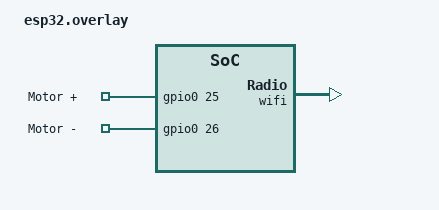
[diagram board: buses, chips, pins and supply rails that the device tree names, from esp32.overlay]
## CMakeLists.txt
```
# SPDX-License-Identifier: Apache-2.0

set(BOARD esp32)
set(CONF_FILE prj.conf)
set(DTC_OVERLAY_FILE esp32.overlay)

cmake_minimum_required(VERSION 3.20.0)

find_package(Zephyr REQUIRED HINTS $ENV{ZEPHYR_BASE})
project(soil_respiration_2023)

include_directories(
                      inc/
                      lib/
                      )

target_sources(app PRIVATE
    src/main.c
    inc/wifi.c
    inc/mqtt.c
    #inc/sockets.c
    inc/sensor.c
    lib/scd30.c
    lib/sensirion_common.c
    inc/ota.c
    inc/motor.c
    inc/ble.c
)
```

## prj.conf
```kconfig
# ############## WIFI ##############
CONFIG_WIFI=y
CONFIG_INIT_STACKS=y
CONFIG_NET_TCP_WORKQ_STACK_SIZE=4096
#CONFIG_HEAP_MEM_POOL_SIZE=98304
CONFIG_HEAP_MEM_POOL_SIZE=60000
CONFIG_NET_L2_WIFI_MGMT=y

CONFIG_NETWORKING=y
CONFIG_NET_IPV4=y
CONFIG_NET_TCP=y
CONFIG_NET_IPV6=n
CONFIG_NET_UDP=y


CONFIG_WIFI_ESP32=y
CONFIG_NET_DHCPV4=y
CONFIG_ESP32_WIFI_STA_AUTO_DHCPV4=y

CONFIG_NET_CONFIG_SETTINGS=y
CONFIG_NET_CONFIG_NEED_IPV4=y

CONFIG_DNS_RESOLVER=y
#CONFIG_DNS_RESOLVER_AI_MAX_ENTRIES=10
CONFIG_NET_SOCKETS=y
CONFIG_DNS_SERVER_IP_ADDRESSES=y
CONFIG_DNS_RESOLVER_ADDITIONAL_BUF_CTR=2



CONFIG_NET_CONFIG_SETTINGS=y

CONFIG_NET_TX_STACK_SIZE=2048
CONFIG_NET_RX_STACK_SIZE=2048

CONFIG_NET_PKT_RX_COUNT=10
CONFIG_NET_PKT_TX_COUNT=10
CONFIG_NET_BUF_RX_COUNT=20
CONFIG_NET_BUF_TX_COUNT=20
CONFIG_NET_MAX_CONTEXTS=10

#Ethernet - building without CONFIG_NET_L2_ETHERNET=y causes fatal error
CONFIG_NET_L2_ETHERNET=y

# logging for debugging wifi
CONFIG_NET_LOG=y
CONFIG_WIFI_LOG_LEVEL_ERR=y
#CONFIG_NET_IPV6_LOG_LEVEL_DBG=y

############## MQTT ##############
CONFIG_MQTT_LIB=y



#LOG
CONFIG_TEST_RANDOM_GENERATOR=y

# HTTP
CONFIG_CBPRINTF_FP_SUPPORT=y
CONFIG_HTTP_CLIENT=y
CONFIG_MINIMAL_LIBC_MALLOC_ARENA_SIZE=4096

#I2C
CONFIG_I2C=y
#GPIO
CONFIG_GPIO=y

#JSON
CONFIG_JSON_LIBRARY=y

CONFIG_MBEDTLS=y
CONFIG_MBEDTLS_ENTROPY_ENABLED=y
CONFIG_MBEDTLS_KEY_EXCHANGE_ECDHE_ECDSA_ENABLED=y
CONFIG_MBEDTLS_ECP_ALL_ENABLED=y

#OTA
CONFIG_BOOTLOADER_MCUBOOT=y

CONFIG_MCUBOOT_IMG_MANAGER=y
CONFIG_FLASH=y
CONFIG_REBOOT=y
CONFIG_HWINFO=y
CONFIG_FLASH_MAP=y
CONFIG_STREAM_FLASH=y
##CONFIG_NET_TCP=y
##CONFIG_NET_SOCKETS=y
CONFIG_IMG_MANAGER=y
##CONFIG_HTTP_CLIENT=y
CONFIG_MPU_ALLOW_FLASH_WRITE=y
CONFIG_IMG_ERASE_PROGRESSIVELY=y
CONFIG_MCUBOOT_EXTRA_IMGTOOL_ARGS="--align 4"

#BLE
CONFIG_BT=y
CONFIG_BT_SMP=y
CONFIG_BT_PERIPHERAL=y
CONFIG_BT_DEVICE_NAME="Zephyr Logger Backend BLE"
CONFIG_LOG_BACKEND_BLE=y
CONFIG_LOG=y
CONFIG_LOG_PROCESS_THREAD_STACK_SIZE=2048
# Uncomment to use the maximum buffer size
CONFIG_BT_L2CAP_TX_MTU=600
CONFIG_BT_BUF_ACL_RX_SIZE=600

#
CONFIG_ESP_HEAP_MEM_POOL_REGION_1_SIZE=4096
```

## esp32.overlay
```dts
/*
 * Copyright (c) 2022 Espressif Systems (Shanghai) Co., Ltd.
 *
 * SPDX-License-Identifier: Apache-2.0
 */

 &wifi {
	status = "okay";
};

/ {
	chosen {
	   zephyr,code-partition = &slot0_partition;
	};
 };

 / {
    aliases {
        sw1 = &motor0;
        sw2 = &motor1;
    };
    gpio_keys {
        compatible = "gpio-keys";
        motor0: motor_0 {
            gpios = <&gpio0 25 GPIO_ACTIVE_HIGH>;
            label = "Motor +";
        };
        motor1: motor_1 {
            gpios = <&gpio0 26 GPIO_ACTIVE_HIGH>;
            label = "Motor -";
        };
    };
};
```

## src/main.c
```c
/*
 * @file src/main
 * @author Thomas Salpietro 45822490
 * @date 02/04/2023
 * @brief main.c - starting threads
 * 
 * SPDX-License-Identifier: Apache-2.0
 */
#include <zephyr/kernel.h>
#include <zephyr/net/http/client.h>

#include <zephyr/logging/log.h>
LOG_MODULE_REGISTER(soil_respiration, LOG_LEVEL_DBG);

#include "wifi.h"
#include "mqtt.h"
#include "sockets.h"
#include "motor.h"
#include "sensor.h"
#include "ble.h"

#define WIFI_STACK_SIZE     4096
#define WIFI_PRIORITY       1

#define MQTT_STACK_SIZE     8192   
#define MQTT_PRIORITY       -3

#define HTTP_STACK_SIZE 	4096
#define HTTP_PRIORITY		-2	

#define SENSOR_STACK_SIZE 	1024
#define SENSOR_PRIORITY		1	

#define MOTOR_STACK_SIZE 	2048
#define MOTOR_PRIORITY		-1	

#define BLE_STACK_SIZE		2048
#define BLE_PRIORITY		-1


K_THREAD_DEFINE(wifi_tid, WIFI_STACK_SIZE,
	thread_wifi_entry, NULL, NULL, NULL,
	WIFI_PRIORITY, 0, 100);

K_THREAD_DEFINE(sensor_tid, SENSOR_STACK_SIZE,
	thread_sensor_entry, NULL, NULL, NULL,
	SENSOR_PRIORITY, 0, 100);


K_THREAD_DEFINE(mqtt_tid, MQTT_STACK_SIZE,
	thread_mqtt_entry, NULL, NULL, NULL,
	MQTT_PRIORITY, 0, 100);

K_THREAD_DEFINE(motor_tid, MOTOR_STACK_SIZE,
	thread_entry_motor, NULL, NULL, NULL,
	MOTOR_PRIORITY, 0, 100);

K_THREAD_DEFINE(ble_tid, BLE_STACK_SIZE,
	ble_thread_entry, NULL, NULL, NULL,
	BLE_PRIORITY, 0, 100);

int main(void) {

    k_thread_start(wifi_tid);
    k_thread_start(mqtt_tid);
	k_thread_start(sensor_tid);
	k_thread_start(motor_tid);

	k_thread_start(ble_tid);

    return 0;
}
```

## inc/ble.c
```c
/**
 ************************************************************************
 * @file inc/ble.c
 * @author Thomas Salpietro 45822490
 * @date 06/04/2023
 * @brief Contains source code for the ble driver
 **********************************************************************
 * */

#include <zephyr/kernel.h>
#include <zephyr/bluetooth/gatt.h>
#include <zephyr/logging/log.h>
#include <zephyr/logging/log_backend_ble.h>

#include "wifi.h"
#include "motor.h"

LOG_MODULE_REGISTER(ble_backend);

#define MAJOR_VERSION 4
#define MINOR_VERSION 1

static const struct bt_data ad[] = {
	BT_DATA_BYTES(BT_DATA_FLAGS, (BT_LE_AD_GENERAL | BT_LE_AD_NO_BREDR)),
	BT_DATA_BYTES(BT_DATA_UUID128_ALL, LOGGER_BACKEND_BLE_ADV_UUID_DATA)
};

static void start_adv(void) {

	int err;

	err = bt_le_adv_start(BT_LE_ADV_CONN_NAME, ad, ARRAY_SIZE(ad), NULL, 0);
	if (err) {
		LOG_ERR("BLE - Advertising failed to start (err %d)", err);
		return;
	}

	LOG_INF("BLE - Advertising successfully started");
}

static void connected(struct bt_conn *conn, uint8_t err) {

	if (err) {
		LOG_ERR("BLE - Connection failed (err 0x%02x)", err);
	} else {
		LOG_INF("BLE - Connected");
	}
}

static void disconnected(struct bt_conn *conn, uint8_t reason) {

	LOG_INF("BLE - Disconnected (reason 0x%02x)", reason);
	start_adv();
}

BT_CONN_CB_DEFINE(conn_callbacks) = {
	.connected = connected,
	.disconnected = disconnected,
};

static void auth_cancel(struct bt_conn *conn) {

	char addr[BT_ADDR_LE_STR_LEN];

	bt_addr_le_to_str(bt_conn_get_dst(conn), addr, sizeof(addr));

	LOG_INF("BLE - Pairing cancelled: %s", addr);
}

static struct bt_conn_auth_cb auth_cb_display = {
	.cancel = auth_cancel,
};

void backend_ble_hook(bool status, void *ctx) {

	ARG_UNUSED(ctx);

	if (status) {
		LOG_INF("BLE Logger Backend enabled: FW Version %d.%d", MAJOR_VERSION, MINOR_VERSION);
	} else {
		LOG_INF("BLE Logger Backend disabled.");
	}
}




void ble_thread_entry(void) {

    int err;

	LOG_INF("BLE LOG Thread");
	logger_backend_ble_set_hook(backend_ble_hook, NULL);
	err = bt_enable(NULL);
	if (err) {
		LOG_ERR("Bluetooth init failed (err %d)", err);
		return 0;
	}

    bt_conn_auth_cb_register(&auth_cb_display);

	start_adv();


    while (1) {
		//uint32_t uptime_secs = k_uptime_get_32()/1000U;

		//LOG_INF("Uptime %d secs", uptime_secs);
		k_sleep(K_MSEC(1000));
        if (!wifiConnected && state != INIT) {
            LOG_ERR("Device not connected to Wi-Fi network - requires a restart");
        }
	}
	//return 0;
    

}
```

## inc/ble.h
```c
/**
 ************************************************************************
 * @file inc/ble.h
 * @author Thomas Salpietro 45822490
 * @date 06/04/2023
 * @brief Contains Macros and definitions for the ble driver
 **********************************************************************
 * */

#ifndef BLE_H
#define BLE_H

void ble_thread_entry(void);

#endif
```

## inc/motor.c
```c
/**
 ************************************************************************
 * @file inc/motor.c
 * @author Thomas Salpietro 45822490
 * @date 06/04/2023
 * @brief Contains source code for the motor driver
 **********************************************************************
 * */

#include <zephyr/kernel.h>
#include <zephyr/device.h>
#include <zephyr/drivers/gpio.h>
#include <zephyr/sys/util.h>
#include <zephyr/logging/log.h>
#include "motor.h"
#include "wifi.h"

LOG_MODULE_REGISTER(soil_respiration_chamber);

//IO 25 and 26
#define SW1_NODE DT_ALIAS(sw1)
#define SW2_NODE DT_ALIAS(sw2)
#define TICKS_PER_SEC               10000
#define FIVE_SEC_TIMEOUT_MS         5000
#define ONE_MIN_TIMEOUT_MS          60000
#define ONE_HOUR_TIMEOUT_MS         3600000
#define FIFTEEN_MIN_TIMEOUT_MS      900000
#define FORTY_FIVE_MIN_TIMEOUT_MS   2700000
#define FIVE_MIN_TIMEOUT_MS         300000
#define SIX_SEC_TIMEOUT_MS          6000

static const struct gpio_dt_spec motorUp = GPIO_DT_SPEC_GET_OR(SW1_NODE, gpios, {0});
static const struct gpio_dt_spec motorDown = GPIO_DT_SPEC_GET_OR(SW2_NODE, gpios, {0});

States state = INIT;
int64_t period = (int64_t)FIFTEEN_MIN_TIMEOUT_MS;


void thread_entry_motor(void) {
    int ret;
    	
    ret = gpio_pin_configure_dt(&motorUp, GPIO_OUTPUT_INACTIVE);
    if (ret != 0) {
		printk("Error %d: failed to configure UP device %s pin %d\n",
		    ret, motorUp.port->name, motorUp.pin);
		//motorUp.port = NULL;
	} else {
		printk("Set up UP at %s pin %d\n", motorUp.port->name, motorUp.pin);
	}


    ret = gpio_pin_configure_dt(&motorDown, GPIO_OUTPUT_INACTIVE);
    if (ret != 0) {
		printk("Error %d: failed to configure DOWN device %s pin %d\n",
		    ret, motorDown.port->name, motorDown.pin);
		//motorDown.port = NULL;
	} else {
		printk("Set up DOWN at %s pin %d\n", motorDown.port->name, motorDown.pin);
	}

    
    int64_t upTime = 0;

    if (!gpio_is_ready_dt(&motorUp)) {
        printk("Up not ready\r\n");
		return 0;
	}
    if (!gpio_is_ready_dt(&motorDown)) {
        printk("down not ready\r\n");
		return 0;
	}

    

    while (true) {
        while (!wifiConnected) {
            //do nothing
            k_msleep(100);
            
        }
        

        switch(state) { 
            case INIT: 
                //init state
                //turn all the way up, then turn all the way down.
                LOG_INF("Initialising Chamber...\r\n");
                gpio_pin_set_dt(&motorUp, 1);
                k_msleep(200);
                gpio_pin_set_dt(&motorDown, 0);
                //printk("Going up\r\n");
                k_msleep(6000);
                gpio_pin_set_dt(&motorUp, 0);
                k_msleep(200);
                gpio_pin_set_dt(&motorDown, 0);
                k_msleep(1000);
                //printk("going down\r\n");
                gpio_pin_set_dt(&motorDown, 1);
                k_msleep(200);
                gpio_pin_set_dt(&motorUp, 0);
                k_msleep(6000);
                gpio_pin_set_dt(&motorDown, 0);
                
                state = SENSING_BEGIN;
                gpio_pin_set_dt(&motorDown, 1);
                gpio_pin_set_dt(&motorUp, 0);
                upTime = k_uptime_get();
                break;
            case SENSING_BEGIN:
                //turn off (DOWN) all the w
                // so if it is already set, we want to check if the uptime has ticked over 5 seconds, then switch off gpio and change state
                if (k_uptime_get() - upTime > (int64_t)SIX_SEC_TIMEOUT_MS) {
                    // so its gone on longer than 5 seconds - turn it off and change state
                    gpio_pin_set_dt(&motorDown, 0);
                    k_msleep(500);
                    gpio_pin_set_dt(&motorUp, 0);
                    upTime = k_uptime_get();
                    state = SENSING;
                    LOG_INF("Begin Sensing... \r\n");
                }
                else {
                    k_msleep(1000);
                }
                
                break;
            case SENSING:
                // this should keep track of time (1 minute), after a minute has passed, change state to SENSING_END
                if (k_uptime_get() - upTime > period) {
                    //1 minute elapsed, change state to sensing end
                    LOG_INF("Done Sensing!");
                    gpio_pin_set_dt(&motorUp, 1);
                    gpio_pin_set_dt(&motorDown, 0);
                    upTime = k_uptime_get();
                    state = SENSING_END;
                } else {
                    //15 minutes still going - do nothing
                    k_msleep(1000);
                }
                break;  
            case SENSING_END:                   
                // so if it is already set, we want to check if the uptime has ticked over 5 seconds, then switch off gpio and change state
                if (k_uptime_get() - upTime > (int64_t)SIX_SEC_TIMEOUT_MS) {
                    // so its gone on longer than 5 seconds - turn it off and change state
                    gpio_pin_set_dt(&motorUp, 0);
                    k_msleep(500);
                    gpio_pin_set_dt(&motorDown, 0);
                    upTime = k_uptime_get();
                    state = SLEEP;
                } else {
                    k_msleep(1000);
                }
                

                break;
            case SLEEP:
                k_msleep(5000);
                // do nothing state - check to see if 1 hour has passed
                if ((k_uptime_get() - upTime) > ((int64_t)ONE_HOUR_TIMEOUT_MS - period - (int64_t)SIX_SEC_TIMEOUT_MS - (int64_t)SIX_SEC_TIMEOUT_MS)) {
                    //one hour has passed - change state
                    state = SENSING_BEGIN;
                    gpio_pin_set_dt(&motorDown, 1);
                    gpio_pin_set_dt(&motorUp, 0);
                    upTime = k_uptime_get();
                } else if ((k_uptime_get() - upTime) % 60000){
                    LOG_INF("Sleep time remaining: %lld minutes", ((int64_t)ONE_HOUR_TIMEOUT_MS - period - (k_uptime_get() - upTime)) / 60000);
                }
                break; 
        }
        k_msleep(100);


    }


}
```

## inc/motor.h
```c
/**
 ************************************************************************
 * @file inc/motor.h
 * @author Thomas Salpietro 45822490
 * @date 06/04/2023
 * @brief Contains Macros and definitions for the motor driver
 **********************************************************************
 * */

#ifndef MOTOR_H
#define MOTOR_H

void thread_entry_motor(void);

//extern bool stateSensing;
//extern bool stateInit;
//extern bool state;

typedef enum states {
    INIT, 
    SENSING_BEGIN, 
    SENSING,
    SENSING_END,
    SLEEP
} States;

extern States state;
extern int64_t period;

#endif
```

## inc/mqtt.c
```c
/**
 ************************************************************************
 * @file inc/mqtt.c
 * @author Thomas Salpietro 45822490
 * @date 06/04/2023
 * @brief Contains source code for the mqtt driver
 **********************************************************************
 * */

/*
    INCLUDES
*/
#include <zephyr/kernel.h>
#include <zephyr/net/mqtt.h>
#include <zephyr/net/socket.h>
#include <string.h>
#include <stdio.h>
#include <stdlib.h>
#include <errno.h>
#include <zephyr/sys/printk.h>
#include <zephyr/sys/util.h>
#include <zephyr/sys/reboot.h>
#include <zephyr/data/json.h>

#include "wifi.h"
#include "sensor.h"
#include "ota.h"
#include "motor.h"




#include <zephyr/logging/log.h>
LOG_MODULE_REGISTER(net_mqtt_publisher, LOG_LEVEL_DBG);

#if defined(CONFIG_MQTT_LIB_WEBSOCKET)
/* Making RX buffer large enough that the full IPv6 packet can fit into it */
#define MQTT_LIB_WEBSOCKET_RECV_BUF_LEN 1280

/* Websocket needs temporary buffer to store partial packets */
static uint8_t temp_ws_rx_buf[MQTT_LIB_WEBSOCKET_RECV_BUF_LEN];
#endif


/*
    MACROS
*/
#define MQTT_CLIENT_ID		    "zephyr_client"
#define SERVER_PORT             1883
#define SERVER_ADDR             "mqtt.tago.io"


#define APP_CONNECT_TIMEOUT_MS  2000
#define APP_SLEEP_MSECS		    500
#define APP_CONNECT_TRIES	    10
#define APP_MQTT_BUFFER_SIZE	4096

#define SIMPLE_HTTP_OTA_MAJOR_VERSION 2
#define SIMPLE_HTTP_OTA_MINOR_VERSION 2

#define RC_STR(rc) ((rc) == 0 ? "OK" : "ERROR")

#define PRINT_RESULT(func, rc) \
	LOG_INF("%s: %d <%s>", (func), rc, RC_STR(rc))

#define SUCCESS_OR_EXIT(rc) { if (rc != 0) { return 1; } }
#define SUCCESS_OR_BREAK(rc) { if (rc != 0) { break; } }

static uint8_t rx_buf[APP_MQTT_BUFFER_SIZE];
static uint8_t tx_buf[APP_MQTT_BUFFER_SIZE];
static uint8_t buffer[APP_MQTT_BUFFER_SIZE];

uint8_t flagOta = 0;

#if defined(CONFIG_DNS_RESOLVER)
static struct zsock_addrinfo hints;
static struct zsock_addrinfo *haddr;
#endif

// MQTT client struct
static struct mqtt_client client_ctx;

// MQTT BROKER parameters
static struct sockaddr_storage broker;

static uint8_t otaTopic[] = "fota/";
static uint8_t periodTopic[] = "period/";
static uint8_t topic[] = "sensor/#";
static struct mqtt_topic subs_topic;
static struct mqtt_subscription_list subs_list;

static struct zsock_pollfd fds[1];
static int nfds;
static bool connected;

struct period_JSON {
    const char *unit;
    const char  *value;
};

static const struct json_obj_descr period_descr[] = {
	JSON_OBJ_DESCR_PRIM(struct period_JSON, unit, JSON_TOK_STRING),
	JSON_OBJ_DESCR_PRIM(struct period_JSON, value, JSON_TOK_STRING),
};

struct period_JSON periodResults;

struct fota_JSON {
    const char *unit;
    const char  *value;
};

static const struct json_obj_descr fota_descr[] = {
	JSON_OBJ_DESCR_PRIM(struct fota_JSON, unit, JSON_TOK_STRING),
	JSON_OBJ_DESCR_PRIM(struct fota_JSON, value, JSON_TOK_STRING),
};

struct fota_JSON fotaResults;


static void prepare_fds(struct mqtt_client *client)
{
	if (client->transport.type == MQTT_TRANSPORT_NON_SECURE) {
		fds[0].fd = client->transport.tcp.sock;
	}
	fds[0].events = ZSOCK_POLLIN;
	nfds = 1;
}


static void clear_fds(void) {
	nfds = 0;
}

static int wait(int timeout)
{
	int ret = 0;

	if (nfds > 0) {
		ret = zsock_poll(fds, nfds, timeout);
		if (ret < 0) {
			LOG_ERR("poll error: %d", errno);
		}
	}

	return ret;
}


static ssize_t handle_published_message(const struct mqtt_publish_param *pub)
{
	int ret;
	size_t received = 0u;
	const size_t message_size = pub->message.payload.len;
	const bool discarded = message_size > APP_MQTT_BUFFER_SIZE;

	LOG_INF("RECEIVED on topic \"%s\" [ id: %u qos: %u ] payload: %u / %u B",
		(const char *)pub->message.topic.topic.utf8, pub->message_id,
		pub->message.topic.qos, message_size, APP_MQTT_BUFFER_SIZE);

	while (received < message_size) {
		uint8_t *p = discarded ? buffer : &buffer[received];

		ret = mqtt_read_publish_payload_blocking(&client_ctx, p, APP_MQTT_BUFFER_SIZE);
		if (ret < 0) {
			return ret;
		}

		received += ret;
	}

	if (!discarded) {
		LOG_HEXDUMP_DBG(buffer, MIN(message_size, 256u), "Received payload:");
	}

	return discarded ? -ENOMEM : received;
}


/*
    MQTT event handler
*/
void mqtt_evt_handler(struct mqtt_client *client,
                      const struct mqtt_evt *evt)
{
    int err;
	switch (evt->type) {
	case MQTT_EVT_CONNACK:
		if (evt->result != 0) {
			LOG_ERR("MQTT connect failed %d", evt->result);
			break;
		}

		connected = true;
		LOG_INF("MQTT client connected!");

		break;

	case MQTT_EVT_DISCONNECT:
		LOG_INF("MQTT client disconnected %d", evt->result);

		connected = false;
        clear_fds();
		break;

	case MQTT_EVT_PUBACK:
		if (evt->result != 0) {
			LOG_ERR("MQTT PUBACK error %d", evt->result);
			break;
		}

		LOG_INF("PUBACK packet id: %u", evt->param.puback.message_id);

		break;

	case MQTT_EVT_PUBREC:
		if (evt->result != 0) {
			LOG_ERR("MQTT PUBREC error %d", evt->result);
			break;
		}

		LOG_INF("PUBREC packet id: %u", evt->param.pubrec.message_id);

		const struct mqtt_pubrel_param rel_param = {
			.message_id = evt->param.pubrec.message_id
		};

		err = mqtt_publish_qos2_release(client, &rel_param);
		if (err != 0) {
			LOG_ERR("Failed to send MQTT PUBREL: %d", err);
		}

		break;

	case MQTT_EVT_PUBCOMP:
		if (evt->result != 0) {
			LOG_ERR("MQTT PUBCOMP error %d", evt->result);
			break;
		}

		LOG_INF("PUBCOMP packet id: %u",
			evt->param.pubcomp.message_id);

		break;

	case MQTT_EVT_PINGRESP:
		LOG_INF("PINGRESP packet");
		break;

	case MQTT_EVT_PUBLISH:
		LOG_INF("PUBLISH received from TAGO");
		const struct mqtt_publish_param *pub = &evt->param.publish;
		
		handle_published_message(pub);

		
		if (!strcmp((const char *)pub->message.topic.topic.utf8, "period/")) {
			// read period payload and update
			json_obj_parse(buffer, sizeof(buffer), period_descr, ARRAY_SIZE(period_descr), &periodResults);
			LOG_INF("Sensor period changed to: %s minutes", periodResults.value);
			period = atoi(periodResults.value) * 1000 * 60;

		} else if (!strcmp((const char *)pub->message.topic.topic.utf8, "fota/") || !strcmp((const char *)pub->message.topic.topic.utf8, "fota/d/")) {
			//FOTA NOW
			
			json_obj_parse(buffer, sizeof(buffer), fota_descr, ARRAY_SIZE(fota_descr), &fotaResults);
			
			//strncpy(host_ip, fotaResults.value, strlen(fotaResults.value));
			LOG_INF("FOTA initiated...");
			flagOta = 1;
		} else {
			//do nothing;
		}


		break;

	default:
		break;
	}
}



static void broker_init(void) {

	struct sockaddr_in *broker4 = (struct sockaddr_in *)&broker;

	broker4->sin_family = AF_INET;
	broker4->sin_port = htons(SERVER_PORT);
#if defined(CONFIG_DNS_RESOLVER)
	net_ipaddr_copy(&broker4->sin_addr,
			&net_sin(haddr->ai_addr)->sin_addr);
#else
	zsock_inet_pton(AF_INET, SERVER_ADDR, &broker4->sin_addr);
#endif

}




/*
    Connect to MQTT Broker
*/
static int connect_to_broker(struct mqtt_client *client)
{
	int rc, i = 0;

	while (i++ < APP_CONNECT_TRIES && !connected) {
		rc = mqtt_connect(client);
		if (rc != 0) {
			PRINT_RESULT("mqtt_connect", rc);
			k_sleep(K_MSEC(APP_SLEEP_MSECS));
			continue;
		}

		prepare_fds(client);

		if (wait(APP_CONNECT_TIMEOUT_MS)) {
			mqtt_input(client);
		}

		if (!connected) {
			mqtt_abort(client);
		}
	}

	if (connected) {
		return 0;
	}

	return -EINVAL;
}

#if defined(CONFIG_DNS_RESOLVER)
static int get_mqtt_broker_addrinfo(void)
{
	int retries = 3;
	int rc = -EINVAL;

	while (retries--) {
		hints.ai_family = AF_INET;
		hints.ai_socktype = SOCK_STREAM;
		hints.ai_protocol = 0;

		rc = zsock_getaddrinfo("mqtt.tago.io", "1883",
				       &hints, &haddr);
		if (rc == 0) {
			LOG_INF("DNS resolved for %s:%d",
			"mqtt.tago.io",
			1883);

			return 0;
		}

		LOG_ERR("DNS not resolved for %s:%d, retrying",
			"mqtt.tago.io",
			1883);
	}

	return rc;
}
#endif

static void subscribe_ota(struct mqtt_client *client)
{
	int err;

	/* subscribe */
	subs_topic.topic.utf8 = otaTopic;
	subs_topic.topic.size = strlen(otaTopic);
	subs_list.list = &subs_topic;
	subs_list.list_count = 1U;
	subs_list.message_id = 1U;
	LOG_INF("Subscribing to %hu topic(s)", subs_list.list_count);

	err = mqtt_subscribe(client, &subs_list);
	if (err) {
		LOG_ERR("Failed on topic %s", otaTopic);
	}
}

static void subscribe_period(struct mqtt_client *client) {
	int err;
	/* subscribe */
	subs_topic.topic.utf8 = periodTopic;
	subs_topic.topic.size = strlen(periodTopic);
	subs_list.list = &subs_topic;
	subs_list.list_count = 1U;
	subs_list.message_id = 1U;
	LOG_INF("Subscribing to %hu topic(s)", subs_list.list_count);

	err = mqtt_subscribe(client, &subs_list);
	if (err) {
		LOG_ERR("Failed on topic %s", otaTopic);
	}
}

static int publish(struct mqtt_client *client, enum mqtt_qos qos, uint8_t topic[])
{
	struct mqtt_publish_param param;
	uint8_t payload[1280];
	(void)snprintf(payload, sizeof(payload),
		       "%f,%f,%f,",
		       (double)sensorData[0], (double)sensorData[1], (double)sensorData[2]);

	param.message.topic.qos = qos;
	param.message.topic.topic.utf8 = topic;
	param.message.topic.topic.size =
			strlen(param.message.topic.topic.utf8);
	param.message.payload.data = payload;
	param.message.payload.len =
			strlen(param.message.payload.data);
	param.message_id = 69;
	param.dup_flag = 0U;
	param.retain_flag = 0U;

	return mqtt_publish(client, &param);
}

static int publish_fw(struct mqtt_client *client, enum mqtt_qos qos, uint8_t topic[])
{
	struct mqtt_publish_param param;
	uint8_t payload[1280];
	(void)snprintf(payload, sizeof(payload),
		       "%d.%d",
		       (int)SIMPLE_HTTP_OTA_MAJOR_VERSION, (int)SIMPLE_HTTP_OTA_MINOR_VERSION);

	param.message.topic.qos = qos;
	param.message.topic.topic.utf8 = topic;
	param.message.topic.topic.size =
			strlen(param.message.topic.topic.utf8);
	param.message.payload.data = payload;
	param.message.payload.len =
			strlen(param.message.payload.data);
	param.message_id = 69;
	param.dup_flag = 0U;
	param.retain_flag = 0U;

	return mqtt_publish(client, &param);
}






int thread_mqtt_entry(void) {

    int rc, val, timeout;
	int ret;
    //init client and broker
	//k_msleep(25000);
	while (!wifiConnected) {
		//do nothing
		k_msleep(1000);
	}
	printk("==MQTT START==\r\n");
	//printk("==FW Ver: %d.%d\r\n", SIMPLE_HTTP_OTA_MAJOR_VERSION, SIMPLE_HTTP_OTA_MINOR_VERSION);
	//k_msleep(15000);
#if defined(CONFIG_DNS_RESOLVER)
	rc = get_mqtt_broker_addrinfo();
	if (rc) {
		printk("Failed to resolve. Thread ended\r\n");
		return 0;
	}
#endif

    mqtt_client_init(&client_ctx);
    broker_init();

    // password and user for tago dashbaord
    struct mqtt_utf8 password;
    struct mqtt_utf8 user;

	password.utf8 = (uint8_t *)"260092b0-8ce9-45a0-9db2-402b4362e14c";
	password.size = strlen("260092b0-8ce9-45a0-9db2-402b4362e14c");

	user.utf8 = (uint8_t *)"Token";
	user.size = strlen("Token");

    /* MQTT client configuration */
    client_ctx.broker = &broker;
    client_ctx.evt_cb = mqtt_evt_handler;
    client_ctx.client_id.utf8 = (uint8_t *) MQTT_CLIENT_ID;
    client_ctx.client_id.size = sizeof(MQTT_CLIENT_ID) - 1;
    client_ctx.password = &password;
    client_ctx.user_name = &user;
    client_ctx.protocol_version = MQTT_VERSION_3_1_1;
    client_ctx.transport.type = MQTT_TRANSPORT_NON_SECURE;

    /* MQTT buffers configuration */
    client_ctx.rx_buf = rx_buf;
    client_ctx.rx_buf_size = sizeof(rx_buf);
    client_ctx.tx_buf = tx_buf;
    client_ctx.tx_buf_size = sizeof(tx_buf);


    // connect to broker - tago io
	printk("Attempting to connect to MQTT Broker\r\n");
	connect_to_broker(&client_ctx);
	
	subscribe_period(&client_ctx);
	subscribe_ota(&client_ctx);
    while (1) {
		if (state == SLEEP) {
			timeout = mqtt_keepalive_time_left(&client_ctx);
			//printk("TIMEOUT: %d\r\n", timeout);
			rc = zsock_poll(&fds[0], 1u, timeout);
			if (rc >= 0) {
				if (fds->revents & ZSOCK_POLLIN) {
					rc = mqtt_input(&client_ctx);
					if (rc != 0) {
						LOG_ERR("Failed to read MQTT input: %d", rc);
						
					} 
				} 
				if (fds->revents & (ZSOCK_POLLHUP | ZSOCK_POLLERR)) {
					LOG_ERR("Socket closed/error");
					
				}
				rc = mqtt_live(&client_ctx);
				if ((rc != 0) && (rc != -EAGAIN)) {
					LOG_ERR("Failed to live MQTT: %d", rc);
					
				}
			} else {
				LOG_ERR("poll failed: %d", rc);
				
			}
		} else {
			timeout = mqtt_keepalive_time_left(&client_ctx);
			//printk("TIMEOUT: %d\r\n", timeout);
			rc = zsock_poll(&fds[0], 1u, 1000);
			if (rc >= 0) {
				if (fds->revents & ZSOCK_POLLIN) {
					rc = mqtt_input(&client_ctx);
					if (rc != 0) {
						LOG_ERR("Failed to read MQTT input: %d", rc);
						
					} 
				} 
				if (fds->revents & (ZSOCK_POLLHUP | ZSOCK_POLLERR)) {
					LOG_ERR("Socket closed/error");
					
				}
				rc = mqtt_live(&client_ctx);
				if ((rc != 0) && (rc != -EAGAIN)) {
					LOG_ERR("Failed to live MQTT: %d", rc);
					
				}
			} else {
				LOG_ERR("poll failed: %d", rc);
				
			}


		}
		//k_msleep(500);
		if (flagOta) {
			// initiate ota
			ret = simple_http_ota_run();
			k_msleep(100);
			if (ret < 0) {
				//ota failed: try again
				flagOta = 1;
			} else {
				flagOta = 0;
				sys_reboot(1);
			}
			
			
		}
		if (sensorTransmit) {
			rc = publish(&client_ctx, MQTT_QOS_1_AT_LEAST_ONCE, topic);
			PRINT_RESULT("mqtt_publish", rc);
			sensorTransmit = false;			
		}

		//k_msleep(1000);

    }

}
```

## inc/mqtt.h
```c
/**
 ************************************************************************
 * @file inc/mqtt.h
 * @author Thomas Salpietro 45822490
 * @date 06/04/2023
 * @brief Contains Macros and definitions for the mqtt driver
 **********************************************************************
 * */

#ifndef MQTT_H
#define MQTT_H

int thread_mqtt_entry(void);

struct fota_JSON {
    const char *unit;
    const char  *value;
};

extern struct fota_JSON fotaResults;


#endif
```

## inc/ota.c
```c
/**
 ************************************************************************
 * @file inc/ota.c
 * @author Thomas Salpietro 45822490
 * @date 06/04/2023
 * @brief Contains source code for the ota driver
 **********************************************************************
 * */

#include <stdio.h>
#include <string.h>
#include <stdlib.h>
#include <zephyr/kernel.h>
#include <zephyr/net/net_ip.h>
#include <zephyr/net/socket.h>
#include <zephyr/net/net_mgmt.h>
#include <zephyr/drivers/flash.h>
#include <zephyr/storage/flash_map.h>
#include <zephyr/dfu/mcuboot.h>
#include <zephyr/dfu/flash_img.h>
#include <zephyr/net/http/client.h>
#include <zephyr/net/http/parser_url.h>
#include <zephyr/sys/reboot.h>

#include <zephyr/logging/log.h>
#include "mqtt.h"
LOG_MODULE_REGISTER(simple_http_ota);

#define SLOT_SIZE1 FLASH_AREA_SIZE(image_1)
#define MAX_RECV_BUF_LEN 512
#define HOST "172.20.10.4"
#define CONFIG_SIMPLE_HTTP_OTA_FILE_URL "http://172.20.10.4/zephyr.signed.bin"
#define CONFIG_SIMPLE_HTTP_OTA_DOWNLOAD_TIMEOUT 30

#define HTTP_TIMEOUT (CONFIG_SIMPLE_HTTP_OTA_DOWNLOAD_TIMEOUT * MSEC_PER_SEC)

/* Copy URL locally so we can parse it */
static char download_url[] = CONFIG_SIMPLE_HTTP_OTA_FILE_URL;

//char host_ip[] = HOST;

enum simple_http_ota_response {
	SIMPLE_HTTP_OTA_OK,
	SIMPLE_HTTP_OTA_ERROR,
};

static struct simple_http_ota_context {
	int sock;
	struct flash_img_context flash_ctx;
	uint8_t recv_buf[MAX_RECV_BUF_LEN];
	enum simple_http_ota_response status;
	size_t content_length;
} ota_context;

int server_connect(struct simple_http_ota_context *ctx)
{
	struct addrinfo *addr;
	struct addrinfo hints;
	char hr_addr[INET6_ADDRSTRLEN];
	char *port;
	int dns_attempts = 3;
	int ret = -1;

	memset(&hints, 0, sizeof(hints));

	hints.ai_socktype = SOCK_STREAM;
	hints.ai_protocol = IPPROTO_TCP;
	if (IS_ENABLED(CONFIG_NET_IPV6)) {
		hints.ai_family = AF_INET6;
	} else if (IS_ENABLED(CONFIG_NET_IPV4)) {
		hints.ai_family = AF_INET;
	}
	port = "80";

	while (dns_attempts--) {
		ret = getaddrinfo("192.168.29.35", port, &hints, &addr);
		if (ret == 0) {
			break;
		}
		k_sleep(K_SECONDS(1));
	}

	if (ret < 0) {
		LOG_ERR("Could not resolve dns, error: %d", ret);
		return ret;
	}

	LOG_DBG("%s address: %s",
		(addr->ai_family == AF_INET ? "IPv4" : "IPv6"),
		net_addr_ntop(addr->ai_family,
			      &net_sin(addr->ai_addr)->sin_addr,
			      hr_addr, sizeof(hr_addr)));

	ctx->sock = socket(hints.ai_family,
			   hints.ai_socktype,
			   hints.ai_protocol);
	if (ctx->sock < 0) {
		LOG_ERR("Failed to create %s HTTP socket (%d)",
			(addr->ai_family == AF_INET ? "IPv4" : "IPv6"),
			-errno);

		freeaddrinfo(addr);
		return -errno;
	}

	if (connect(ctx->sock, addr->ai_addr, addr->ai_addrlen) < 0) {
		LOG_ERR("Cannot connect to %s remote (%d)",
			(addr->ai_family == AF_INET ? "IPv4" : "IPv6"),
			-errno);

		freeaddrinfo(addr);
		return -errno;
	}

	freeaddrinfo(addr);

	return 0;
}

static int setup_socket(sa_family_t family, const char *server, int port,
			int *sock, struct sockaddr *addr, socklen_t addr_len)
{
	int ret = 0;

	memset(addr, 0, addr_len);

	if (family == AF_INET) {
		net_sin(addr)->sin_family = AF_INET;
		net_sin(addr)->sin_port = htons(port);
		inet_pton(family, server, &net_sin(addr)->sin_addr);
	}

	*sock = socket(family, SOCK_STREAM, IPPROTO_TCP);

	if (*sock < 0) {
		LOG_ERR("Failed to create HTTP socket (%d)", -errno);
	}

	return ret;
}

static int connect_socket(sa_family_t family, const char *server, int port,
			  int *sock, struct sockaddr *addr, socklen_t addr_len)
{
	int ret;

	ret = setup_socket(family, server, port, sock, addr, addr_len);
	if (ret < 0 || *sock < 0) {
		LOG_ERR("could create socket (%d)", ret);
		return -1;
	}

	ret = connect(*sock, addr, addr_len);
	if (ret < 0) {
		LOG_ERR("Cannot connect to remote (%d)", -errno);
		ret = -errno;
	}

	return ret;
}

static void response_cb(struct http_response *rsp,
			enum http_final_call final_data,
			void *user_data)
{
	static size_t body_len;
	uint8_t *body_data = NULL;
	int ret = 0;

	/* check if file exists and its size */
	if (rsp->http_status_code != 200) {
		ota_context.status = SIMPLE_HTTP_OTA_ERROR;
		LOG_ERR("Could not download file: HTTP error %d", rsp->http_status_code);
		return;
	}

	if (rsp->content_length > SLOT_SIZE1) {
		ota_context.status = SIMPLE_HTTP_OTA_ERROR;
		LOG_ERR("File size too big (got %d, max is %d)",
				rsp->content_length, SLOT_SIZE1);
		return;
	}

	if (ota_context.content_length == 0) {
		body_data = rsp->body_frag_start;
		body_len = rsp->data_len;
		body_len -= (rsp->body_frag_start - rsp->recv_buf);

		ota_context.content_length = rsp->content_length;
	} else {
		body_data = rsp->body_frag_start;
		body_len = rsp->data_len;
	}

	if ((rsp->body_found == 1) && (body_data == NULL)) {
		body_data = rsp->recv_buf;
		body_len = rsp->data_len;
	}

	if (body_data != NULL) {
		ret = flash_img_buffered_write(&ota_context.flash_ctx, body_data, body_len, false);
		if (ret < 0) {
			ota_context.status = SIMPLE_HTTP_OTA_ERROR;
			LOG_ERR("Flash write error %d", ret);
			return;
		}
	}
}

int simple_http_ota_run(void)
{
	struct sockaddr_in addr4;
	int ret = 0;
	char uri[64];
	char host[64];
	int port = 80;

	struct http_parser_url parser;
	uint16_t off, len;

	flash_img_init(&ota_context.flash_ctx);

	http_parser_url_init(&parser);
	ret = http_parser_parse_url(download_url, strlen(download_url), 0, &parser);
	if (ret < 0) {
		LOG_ERR("Invalid url: %s", download_url);
		return -ENOTSUP;
	}

	/* parse URL schema address */
	off = parser.field_data[UF_SCHEMA].off;
	len = parser.field_data[UF_SCHEMA].len;

	/* check for supported protocol */
	if (strncmp(download_url + off, "http://", len) != 0) {
		LOG_ERR("Only http URL is supported");
		return -EPROTONOSUPPORT;
	}

	/* parse host address */
	off = parser.field_data[UF_HOST].off;
	len = parser.field_data[UF_HOST].len;
	//strncpy(host, download_url+off, len);
	memset(host, 0, 64);
	strncpy(host, fotaResults.value, strlen(fotaResults.value));
	//host[len] = '\0';
	printk("HOST: %s\r\n", host);

	/* parse uri address */
	off = parser.field_data[UF_PATH].off;
	len = parser.field_data[UF_PATH].len;
	//strncpy(uri, download_url+off, len);
	memset(uri, 0, 64);
	strncpy(uri, "/zephyr.signed.bin", strlen("/zephyr.signed.bin"));
	//uri[len] = '\0';
	printk("URI: %s\r\n", uri);

	/* set custom port */
	if ((parser.field_set & (1 << UF_PORT))) {
		port = parser.port;
	}

	LOG_INF("URL: http://%s:%d%s", host, port, uri);

	connect_socket(AF_INET, host, port, &ota_context.sock,
					(struct sockaddr *)&addr4, sizeof(addr4));

	//server_connect(&ota_context);
	if (ota_context.sock < 0) {
		LOG_ERR("Cannot create HTTP connection.");
		return -ECONNABORTED;
	}

	if (ota_context.sock >= 0) {
		struct http_request req;

		memset(&req, 0, sizeof(req));

		req.method = HTTP_GET;
		req.url = uri;
		req.host = host;
		req.protocol = "HTTP/1.1";
		req.response = response_cb;
		req.recv_buf = ota_context.recv_buf;
		req.recv_buf_len = sizeof(ota_context.recv_buf);

		ota_context.content_length = 0;
		ota_context.status = SIMPLE_HTTP_OTA_OK;

		ret = http_client_req(ota_context.sock, &req, HTTP_TIMEOUT, NULL);
		if (ret < 0 || ota_context.status != SIMPLE_HTTP_OTA_OK) {
			LOG_ERR("Error downloading file ret = %d", ret);
		} else {
			/* finish image flashing in here */
			int ret = flash_img_buffered_write(&ota_context.flash_ctx, NULL, 0, true);

			if (ret < 0) {
				LOG_ERR("Flash write error %d", ret);
			}

			/* perform boot upgrade check */
			if (boot_request_upgrade(BOOT_UPGRADE_TEST) == 0) {
				LOG_INF("Update installed. Restart the board to complete.");
			} else {
				LOG_ERR("Update not installed. File is corrupted or invalid.");
				ret = -1;
			}
		}
	}

	if (ota_context.sock >= 0) {
		close(ota_context.sock);
	}

	return ret;
}

int simple_http_ota_init(void)
{
	bool image_ok = false;
	int ret = 0;

	image_ok = boot_is_img_confirmed();
	LOG_INF("Image is%s confirmed OK", image_ok ? "" : " not");
	if (!image_ok) {
		ret = boot_write_img_confirmed();
		if (ret < 0) {
			LOG_ERR("Couldn't confirm this image: %d", ret);
			return ret;
		}

		LOG_INF("Erasing bank in slot 1...");
		ret = boot_erase_img_bank(FLASH_AREA_ID(image_1));
		if (ret) {
			LOG_ERR("Failed to erase second slot");
			return ret;
		}
	}

	return ret;
}
```

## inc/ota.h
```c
/**
 ************************************************************************
 * @file inc/ota.h
 * @author Thomas Salpietro 45822490
 * @date 02/04/2023
 * @brief Contains macros for the ota driver 
 **********************************************************************
 * */

#ifndef MQTT_H
#define MQTT_H



/**
 * @brief Init application
 *
 * Performs MCUBoot image check
 *
 * @return 0 on success
 * @return other error code returned by MCUBoot initialization
 */
int simple_http_ota_init(void);

/**
 * @brief Init over-the-air update
 *
 * This call starts http client to retrieve file information, performs
 * download and proper flashing into slot 1.
 *
 * @return 0 on success
 * @return other error code returned by HTTP and Flash API.
 */
int simple_http_ota_run(void);

//extern char host_ip[64];

#endif /* __SIMPLE_HTTP_OTA_H__ */
```

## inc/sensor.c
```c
/**
 ************************************************************************
 * @file inc/sensor.c
 * @author Thomas Salpietro 45822490
 * @date 02/04/2023
 * @brief Contains source code for the sensor driver
 **********************************************************************
 * */


#include <zephyr/kernel.h>
#include <zephyr/device.h>
#include <stdio.h>
#include <zephyr/logging/log.h>

#include "scd30.h"
#include "sensirion_common.h"
#include "sensor.h"
#include "motor.h"

LOG_MODULE_REGISTER(soil_respiration_sensor);

#define SCD30_ALIAS     DT_ALIAS(i2c_0)

float sensorData[3];
bool sensorTransmit = false;


void thread_sensor_entry(void) {

    // variables
    float co2, temperature, relativeHumidity;
    int16_t err;
    uint16_t dataReady, ver;
    uint16_t intervalSeconds = 5;
    uint16_t timeout = 0;


    //i2c dev
    const struct device *i2cDev = DEVICE_DT_GET(SCD30_ALIAS);

    if (!device_is_ready(i2cDev)) {
		printk("I2C: Device is not ready.\r\n");
		return;
	}


    scd30_get_driver_version(&ver, i2cDev);
    printk("Device ready. Firmware Version: %d\r\n", ver);

    //k_msleep(25000);
    // set measurment interval - 2 seconds
    scd30_set_measurement_interval(intervalSeconds, i2cDev);
    // start measurements
    scd30_start_periodic_measurement(0, i2cDev);

    while(1) {
        if (state == SENSING){
            scd30_get_data_ready(&dataReady, i2cDev);

            
            if (dataReady) {
                //get co2
                err = scd30_read_measurement(&sensorData[0], &sensorData[1], &sensorData[2], i2cDev);
                if (err != NO_ERROR) {
                    LOG_ERR("error reading measurement\r\n");
                } else {
                    LOG_INF("measured co2 concentration: %0.2f ppm, "
                    "measured temperature: %0.2f degreeCelsius, "
                    "measured humidity: %0.2f %%RH\r\n",
                    sensorData[0], sensorData[1], sensorData[2]);
                    sensorTransmit = true;
                }
            }
        } else {
            k_msleep(5000);
        }
        /*
        else if (state == SENSING_END) {
            scd30_stop_periodic_measurement(i2cDev);
            k_msleep(4000);
        } else if (state == SENSING_BEGIN) {
            scd30_start_periodic_measurement(0, i2cDev);
            k_msleep(4000);
        }*/
        

        

    }



    
}
```

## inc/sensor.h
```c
/**
 ************************************************************************
 * @file inc/sensor.h
 * @author Thomas Salpietro 45822490
 * @date 02/04/2023
 * @brief Contains macros for the sensor driver 
 **********************************************************************
 * */

#ifndef SENSOR_H
#define SENSOR_H

void thread_sensor_entry(void);


extern float sensorData[3];
extern bool sensorTransmit;

#endif
```

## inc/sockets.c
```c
/**
 ************************************************************************
 * @file inc/sockets.c
 * @author Thomas Salpietro 45822490
 * @date 02/04/2023
 * @brief Contains source code for the sockets driver for http
 **********************************************************************
 * */

#include <zephyr/logging/log.h>
LOG_MODULE_DECLARE(soil_respiration, LOG_LEVEL_DBG);

#include <zephyr/net/net_ip.h>
#include <zephyr/net/socket.h>
#include <zephyr/net/socketutils.h>
#include <zephyr/net/dns_resolve.h>
#include <zephyr/net/tls_credentials.h>
#include <zephyr/net/http/client.h>
#include <zephyr/random/rand32.h>
#include <stdio.h>
#include <zephyr/kernel.h>

#include "sockets.h"
#include "wifi.h"
#include "sensor.h"

#define TAGOIO_SERVER 				"75.2.65.153"
//#define TAGOIO_SERVER				"api.tago.io"


#define TAGOIO_URL          		"/data"
#define HTTP_PORT           		"80"
#define DEVICE_TOKEN				"bed51d18-2744-4e8d-8959-232ab7ff5730"
#define HTTP_CONN_TIMEOUT			10
#define HTTP_PUSH_INTERVAL			10

static struct tagoio_context ctx;

static const char *tagoio_http_headers[] = {
	"Device-Token: bed51d18-2744-4e8d-8959-232ab7ff5730\r\n",
	"Content-Type: application/json\r\n",
	"_ssl: false\r\n",
	NULL
};

int tagoio_connect(struct tagoio_context *ctx)
{
	struct addrinfo *addr;
	struct addrinfo hints;
	char hr_addr[INET6_ADDRSTRLEN];
	char *port;
	int dns_attempts = 3;
	int ret = -1;

	memset(&hints, 0, sizeof(hints));

	hints.ai_socktype = SOCK_STREAM;
	hints.ai_protocol = IPPROTO_TCP;
	if (IS_ENABLED(CONFIG_NET_IPV6)) {
		hints.ai_family = AF_INET6;
	} else if (IS_ENABLED(CONFIG_NET_IPV4)) {
		hints.ai_family = AF_INET;
	}
	port = HTTP_PORT;

	while (dns_attempts--) {
		ret = getaddrinfo(TAGOIO_SERVER, port, &hints, &addr);
		if (ret == 0) {
			break;
		}
		k_sleep(K_SECONDS(1));
	}

	if (ret < 0) {
		LOG_ERR("Could not resolve dns, error: %d", ret);
		return ret;
	}

	LOG_DBG("%s address: %s",
		(addr->ai_family == AF_INET ? "IPv4" : "IPv6"),
		net_addr_ntop(addr->ai_family,
			      &net_sin(addr->ai_addr)->sin_addr,
			      hr_addr, sizeof(hr_addr)));

	ctx->sock = socket(hints.ai_family,
			   hints.ai_socktype,
			   hints.ai_protocol);
	if (ctx->sock < 0) {
		LOG_ERR("Failed to create %s HTTP socket (%d)",
			(addr->ai_family == AF_INET ? "IPv4" : "IPv6"),
			-errno);

		freeaddrinfo(addr);
		return -errno;
	}

	if (connect(ctx->sock, addr->ai_addr, addr->ai_addrlen) < 0) {
		LOG_ERR("Cannot connect to %s remote (%d)",
			(addr->ai_family == AF_INET ? "IPv4" : "IPv6"),
			-errno);

		freeaddrinfo(addr);
		return -errno;
	}

	freeaddrinfo(addr);

	return 0;
}

int tagoio_http_push(struct tagoio_context *ctx,
		     http_response_cb_t resp_cb)
{
	struct http_request req;
	int ret;

	memset(&req, 0, sizeof(req));

	req.method		= HTTP_POST;
	req.host		= TAGOIO_SERVER;
	req.port		= HTTP_PORT;
	req.url			= TAGOIO_URL;
	req.header_fields	= tagoio_http_headers;
	req.protocol		= "HTTP/1.1";
	req.response		= resp_cb;
	req.payload		= ctx->payload;
	req.payload_len		= strlen(ctx->payload);
	req.recv_buf		= ctx->resp;
	req.recv_buf_len	= sizeof(ctx->resp);

	ret = http_client_req(ctx->sock, &req,
			      HTTP_CONN_TIMEOUT * MSEC_PER_SEC,
			      ctx);

	close(ctx->sock);
	ctx->sock = -1;

	return ret;
}




static void response_cb(struct http_response *rsp,
			enum http_final_call final_data,
			void *user_data)
{
	if (final_data == HTTP_DATA_MORE) {
		LOG_DBG("Partial data received (%zd bytes)", rsp->data_len);
	} else if (final_data == HTTP_DATA_FINAL) {
		LOG_DBG("All the data received (%zd bytes)", rsp->data_len);
	}

	LOG_DBG("Response status %s", rsp->http_status);
}

static int collect_data(void)
{
	#define lower 20000
	#define upper 100000
	#define base  1000.00f

	float temp;

	/* Generate a temperature between 20 and 100 celsius degree */
	/* SWAP THESE TWO LINES WITH GET FROM QUEUE OR SOMETHING*/
	//temp = ((sys_rand32_get() % (upper - lower + 1)) + lower);
	//temp /= base;


	(void)snprintf(ctx.payload, sizeof(ctx.payload),
		       "{\"variable\": \"co2\","
		       "\"unit\": \"ppm\",\"value\": %f}",
		       (double)sensorData[0]);

	/* LOG doesn't print float #18351 */
	LOG_INF("CO2: %d", (int) sensorData[0]);

	return 0;
}

static void next_turn(void)
{
	if (collect_data() < 0) {
		LOG_INF("Error collecting data.");
		return;
	}

	if (tagoio_connect(&ctx) < 0) {
		LOG_INF("No connection available.");
		return;
	}

	if (tagoio_http_push(&ctx, response_cb) < 0) {
		LOG_INF("Error pushing data.");
		return;
	}
}

void thread_http_entry(void)
{
	LOG_INF("TagoIO IoT - HTTP Client - Soil Respiration");

	

	while (true) {
		printk("SEMAPHORE COUNT: %d\r\n", k_sem_count_get(&wifiSem));
		if (k_sem_count_get(&wifiSem) ==  0) {
			//semaphore taken: wifi connected
			next_turn();
		} else {
			continue;
		}
		

		k_sleep(K_SECONDS(HTTP_PUSH_INTERVAL));
	}
}
```

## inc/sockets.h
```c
/**
 ************************************************************************
 * @file inc/sockets.h
 * @author Thomas Salpietro 45822490
 * @date 02/04/2023
 * @brief Contains macros for the sockets driver for http
 **********************************************************************
 * */


#ifndef HTTP_H
#define HTTP_H

#define TAGOIO_SOCKET_MAX_BUF_LEN 1280

struct tagoio_context {
	int sock;
	uint8_t payload[TAGOIO_SOCKET_MAX_BUF_LEN];
	uint8_t resp[TAGOIO_SOCKET_MAX_BUF_LEN];
};

int tagoio_connect(struct tagoio_context *ctx);
int tagoio_http_push(struct tagoio_context *ctx,
		     http_response_cb_t resp_cb);

void thread_http_entry(void);

#endif
```
